# M4G9 register map
File version: 0.1
Registers are 32-bit, read-write, reset 0x0 unless marked. A register's access mark holds for its fields unless they carry their own. Offsets are from the block's base; [hi:lo] are bit positions; {n}, {i} and the like mark numbered series.

## PW — Port W
Base 0x400E1200
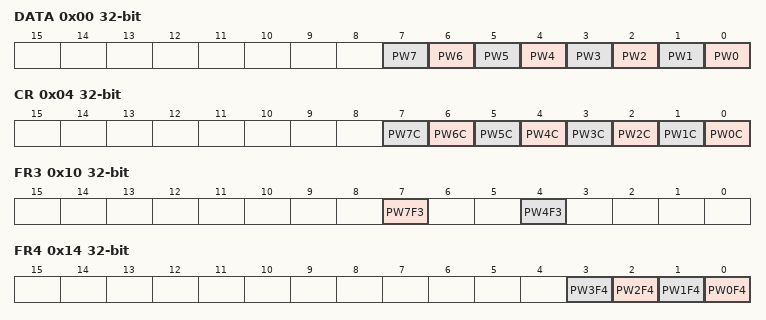
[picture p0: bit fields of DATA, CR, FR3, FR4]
0x00 DATA — Port W Data Register
  [n] PW{n} (n=0..7)
0x04 CR — Port W OutPut Control Register
  [n] PW{n}C (n=0..7)
0x10 FR3 — Port W Function Register 3
  [7] PW7F3, [4] PW4F3
0x14 FR4 — Port W Function Register 4
  [n] PW{n}F4 (n=0..3)
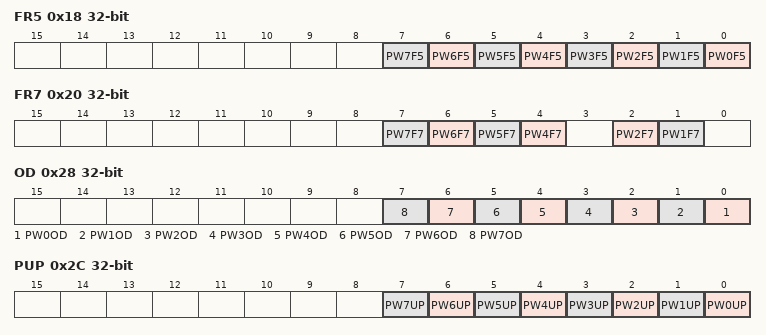
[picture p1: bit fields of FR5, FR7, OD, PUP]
0x18 FR5 — Port W Function Register 5
  [n] PW{n}F5 (n=0..7)
0x1C FR6 — Port W Function Register 6
  [0] PW0F6
0x20 FR7 — Port W Function Register 7
  [n] PW{n}F7 (n=4..7), [2] PW2F7, [1] PW1F7
0x28 OD — Port W Open Drain Control Register
  [n] PW{n}OD (n=0..7)
0x2C PUP — Port W Pull-up Control Register
  [n] PW{n}UP (n=0..7)
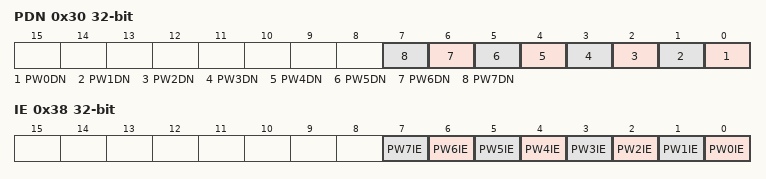
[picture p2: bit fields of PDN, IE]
0x30 PDN — Port W Pull-down Control Register
  [n] PW{n}DN (n=0..7)
0x38 IE — Port W InPut Control Register
  [n] PW{n}IE (n=0..7)

## PY — Port Y
Base 0x400E1300
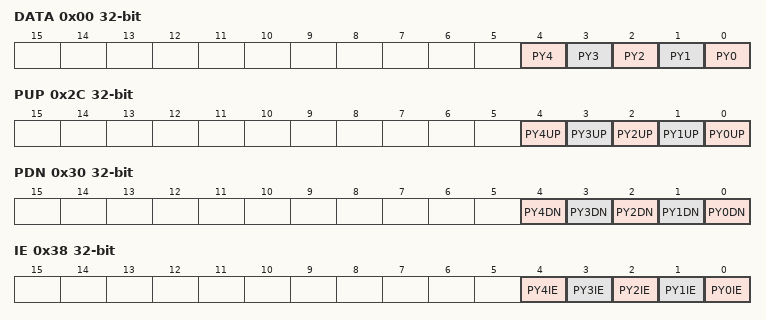
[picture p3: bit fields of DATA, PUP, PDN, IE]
0x00 DATA — Port Y Data Register
  [n] PY{n} (n=0..4)
0x04 CR — Port Y OutPut Control Register
  [4] PY4C
0x08 FR1 — Port Y Function Register 1
  [4] PY4F1
0x14 FR4 — Port Y Function Register 4
  [4] PY4F4
0x28 OD — Port Y Open Drain Control Register
  [4] PY4OD
0x2C PUP — Port Y Pull-up Control Register
  [n] PY{n}UP (n=0..4)
0x30 PDN — Port Y Pull-down Control Register
  [n] PY{n}DN (n=0..4)
0x38 IE — Port Y InPut Control Register
  [n] PY{n}IE (n=0..4)

## TRMOSC — Internal High-speed Oscillation Adjustment
Base 0x400E3100
0x00 PRO — Protection Register
  [7:0] PROTECT
0x04 EN — Enable Register
  [0] TRIMEN
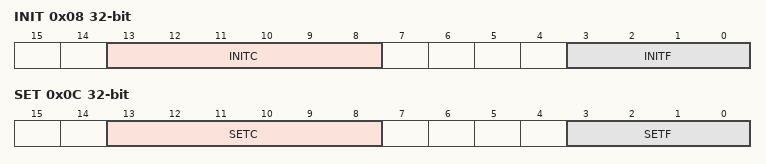
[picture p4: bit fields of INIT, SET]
0x08 INIT ro (reset mask 0xFFFFC0F0) — Initial Trimming Level Monitor Register
  [13:8] INITC, [3:0] INITF
0x0C SET — Trimming Level Setting Register
  [13:8] SETC, [3:0] SETF

## OFD — Oscillation Frequency Detector (OFD)
Base 0x400E4000
0x00 CR1 reset 0x6 — OFD Control Register 1
  [7:0] OFDWEN
0x04 CR2 — OFD Control Register 2
  [7:0] OFDEN
0x08 MN0 — OFD Lower Detection Frequency Setting Register0
  [11:0] OFDMN0
0x0C MN1 — OFD Lower Detection Frequency Setting Register1
  [11:0] OFDMN1
0x10 MX0 — OFD Higher Detection Frequency Setting Register0
  [11:0] OFDMX0
0x14 MX1 — OFD Higher Detection Frequency Setting Register1
  [11:0] OFDMX1
0x18 RST reset 0x1 — OFD Reset Enable Control Register
  [0] OFDRSTEN
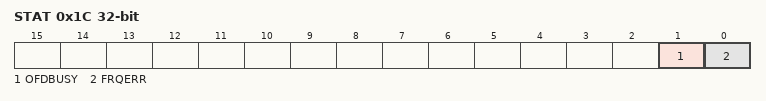
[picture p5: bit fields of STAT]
0x1C STAT ro — OFD Status Register
  [1] OFDBUSY, [0] FRQERR
0x20 MON reset 0x1 — OFD External high frequency oscillaion clock monitor register
  [0] OFDMON

## RTC — Real Time Clock (RTC)
Base 0x400E4800
0x00 SECR 8-bit (reset mask 0x80) — RTC Sec setting register
  [6:0] SE
0x01 MINR 8-bit (reset mask 0x80) — RTC Min settging register
  [6:0] MI
0x02 HOURR 8-bit (reset mask 0xC0) — RTC Hour setting register
  [5:0] HO
0x04 DAYR 8-bit (reset mask 0xF8) — RTC Day setting register
  [2:0] WE
0x05 DATER 8-bit (reset mask 0xC0) — RTC Date setting register
  [5:0] DA
0x06 MONTHR_A 8-bit (reset mask 0xE0) — RTC Month settging register PAGE0
  [4:0] MO
0x06 MONTHR_B 8-bit (reset mask 0xFE) (RTC_MONTHR view) — RTC Month settging register PAGE0
  [0] MO0
0x07 YEARR_A 8-bit reset not defined — RTC Year setting register PAGE0
  [7:0] YE
0x07 YEARR_B 8-bit (reset mask 0xFC) (RTC_YEARR view) — RTC Leap year register PAGE1
  [1:0] LEAP
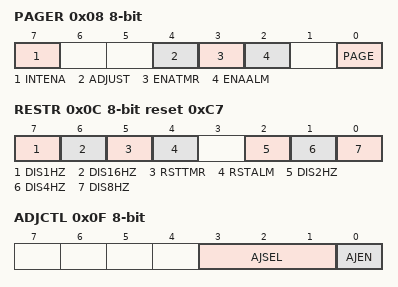
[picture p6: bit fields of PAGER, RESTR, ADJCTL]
0x08 PAGER 8-bit (reset mask 0xF3) — RTC Page register
  [7] INTENA, [4] ADJUST, [3] ENATMR, [2] ENAALM, [0] PAGE
0x0C RESTR 8-bit reset 0xC7 — RTC Reset register
  [7] DIS1HZ, [6] DIS16HZ, [5] RSTTMR, [4] RSTALM, [2] DIS2HZ, [1] DIS4HZ, [0] DIS8HZ
0x0E PROTECT 8-bit reset 0xC1 — RTC clock adjust control register
0x0F ADJCTL 8-bit — RTC protect register
  [3:1] AJSEL, [0] AJEN
0x10 ADJDAT 8-bit reset not defined — RTC clock adjust data register
0x11 ADJSIGN 8-bit (reset mask 0xFE)
  [0] ADJSIGN

## CEC — Consumer Electronics Control (CEC)
Base 0x400E8000
0x00 EN — CEC Enable Register
  [0] CECEN
0x04 ADD — CEC Logical Address Register
  [15:0] CECADD
0x08 RESET wo — CEC Software Reset Register
  [0] CECRESET
0x0C REN (reset mask 0xFFFFFFFE) — CEC Receive Enable Register
  [0] CECREN
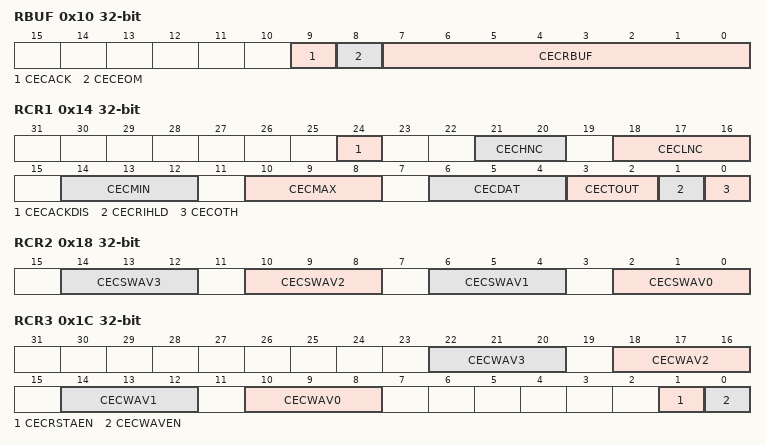
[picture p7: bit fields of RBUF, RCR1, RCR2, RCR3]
0x10 RBUF ro — CEC Receive Buffer Register
  [9] CECACK, [8] CECEOM, [7:0] CECRBUF
0x14 RCR1 — CEC Receive Control Register 1
  [24] CECACKDIS, [21:20] CECHNC, [18:16] CECLNC, [14:12] CECMIN, [10:8] CECMAX, [6:4] CECDAT, [3:2] CECTOUT, [1] CECRIHLD, [0] CECOTH
0x18 RCR2 — CEC Receive Control Register 2
  [4n+2:4n] CECSWAV{n} (n=0..3)
0x1C RCR3 — CEC Receive Control Register 3
  [4n+10:4n+8] CECWAV{n} (n=0..3), [1] CECRSTAEN, [0] CECWAVEN
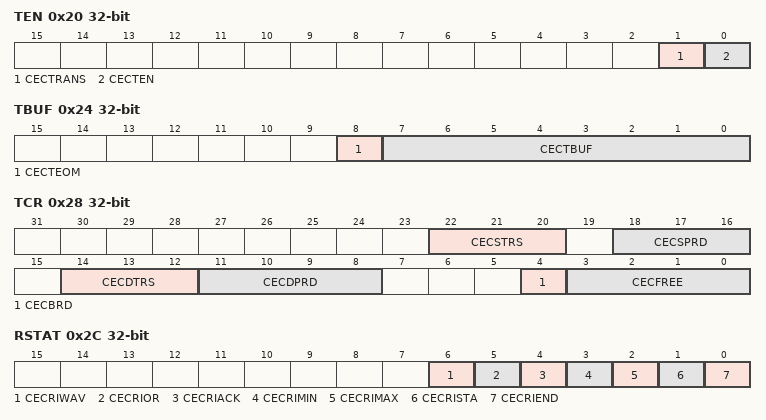
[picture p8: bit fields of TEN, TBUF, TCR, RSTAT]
0x20 TEN (reset mask 0xFFFFFFFE) — CEC Transmit Enable Register
  [1] CECTRANS ro, [0] CECTEN wo
0x24 TBUF — CEC Transmit Buffer Register
  [8] CECTEOM, [7:0] CECTBUF
0x28 TCR — CEC Transmit Control Register
  [22:20] CECSTRS, [18:16] CECSPRD, [14:12] CECDTRS, [11:8] CECDPRD, [4] CECBRD, [3:0] CECFREE
0x2C RSTAT ro — CEC Receive Interrupt Status Register
  [6] CECRIWAV, [5] CECRIOR, [4] CECRIACK, [3] CECRIMIN, [2] CECRIMAX, [1] CECRISTA, [0] CECRIEND
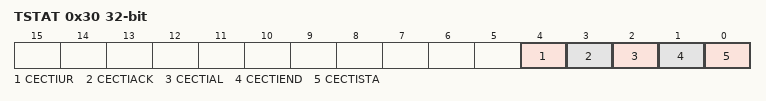
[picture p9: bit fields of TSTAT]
0x30 TSTAT ro — CEC Transmit Interrupt Status Register
  [4] CECTIUR, [3] CECTIACK, [2] CECTIAL, [1] CECTIEND, [0] CECTISTA
0x34 FSSEL — CEC sampling clock selection Register
  [0] CECCLK
